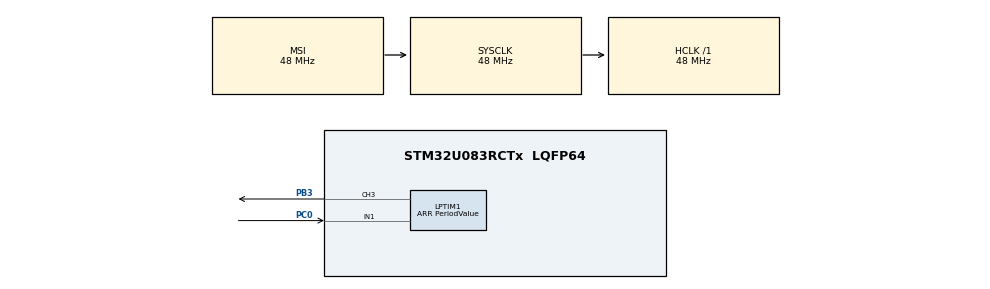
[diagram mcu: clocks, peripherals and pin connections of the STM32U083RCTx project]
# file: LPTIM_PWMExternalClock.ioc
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LPTIM1.OCPolarity_3=LPTIM_OCPOLARITY_LOW
LPTIM1.OCPulse_3=PulseValue
LPTIM1.Period=PeriodValue
Mcu.Family=STM32U0
Mcu.Name=STM32U083RCTx
Mcu.Package=LQFP64
NVIC.PriorityGroup=NVIC_PRIORITYGROUP_2
PB3.GPIO_PuPd=GPIO_PULLUP
PB3.GPIO_Speed=GPIO_SPEED_FREQ_HIGH
PB3.Signal=S_LPTIM1_CH3
PC0.Mode=Counts_external_clock_standalone_1X_occur1
PC0.Signal=LPTIM1_IN1
ProjectManager.HeapSize=0x200
ProjectManager.StackSize=0x400
ProjectManager.TargetToolchain=EWARM V9.20
RCC.ADCFreq_Value=48000000
RCC.AHBFreq_Value=48000000
RCC.CodegenConfigPeriph=false
RCC.CortexFreq_Value=48000000
RCC.HCLKFreq_Value=48000000
RCC.HSE_VALUE=4000000
RCC.HSI48_VALUE=48000000
RCC.HSI_VALUE=16000000
RCC.LSE_VALUE=32768
RCC.MSIClockRangeVal=RCC_MSIRANGE_11
RCC.MSI_VALUE=48000000
RCC.PLLM=RCC_PLLM_DIV8
RCC.PLLN=8
RCC.PLLSourceVirtual=RCC_PLLSOURCE_MSI
RCC.SYSCLKFreq_VALUE=48000000
RCC.SYSCLKSource=RCC_SYSCLKSOURCE_MSI
RCC.USBFreq_Value=48000000
RCC.VCOOutputFreq_Value=48000000
SH.S_LPTIM1_CH3.0=LPTIM1_CH3,OutputIO_CH3
VP_LPTIM1_VS_CH3.Mode=Channel_3_Active
VP_PWR_VS_SECSignals.Mode=Security/Privilege
board=custom

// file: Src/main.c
/* USER CODE BEGIN Header */
/**
  ******************************************************************************
  * @file    LPTIM/LPTIM_PWMExternalClock/Src/main.c
  * @author  MCD Application Team
  * @brief   This example describes how to configure and use LPTIM to generate a
  *          PWM at the lowest power consumption, using an external counter
  *          clock, through the STM32U0xx HAL API.
  ******************************************************************************
  * @attention
  *
  * Copyright (c) 2023 STMicroelectronics.
  * All rights reserved.
  *
  * This software is licensed under terms that can be found in the LICENSE file
  * in the root directory of this software component.
  * If no LICENSE file comes with this software, it is provided AS-IS.
  ******************************************************************************
  */
/* USER CODE END Header */
#include "main.h"

/* USER CODE BEGIN PD */
/* Set the timeout to 1000 ms */
#define TIMEOUT_VALUE 1000U

/* USER CODE END PD */

LPTIM_HandleTypeDef hlptim1;

void SystemClock_Config(void);
static void MX_GPIO_Init(void);
static void MX_LPTIM1_Init(void);

int main(void)
{
  /* USER CODE BEGIN 1 */
  uint32_t tickstart;
  /* STM32U0xx HAL library initialization:
       - Configure the Flash prefetch
       - Systick timer is configured by default as source of time base, but user
         can eventually implement his proper time base source (a general purpose
         timer for example or other time source), keeping in mind that Time base
         duration should be kept 1ms since PPP_TIMEOUT_VALUEs are defined and
         handled in milliseconds basis.
       - Low Level Initialization
     */
  /* USER CODE END 1 */

  /* MCU Configuration--------------------------------------------------------*/

  /* Reset of all peripherals, Initializes the Flash interface and the Systick. */
  HAL_Init();

  /* Configure the system clock */
  SystemClock_Config();

  /* USER CODE BEGIN SysInit */
  /* Configure LED4 */
  BSP_LED_Init(LED4);

  /* USER CODE END SysInit */

  /* Initialize all configured peripherals */
  MX_GPIO_Init();
  MX_LPTIM1_Init();
  /* USER CODE BEGIN 2 */

  /* User push-button (EXTI_Line13) will be used to wakeup the system from STOP mode */
  BSP_PB_Init(BUTTON_USER, BUTTON_MODE_EXTI);

  /* ### Start generating the PWM signal ############################## */
  /*
   *  Period = 99
   *  Pulse  = 49
   *  According to this configuration, the duty cycle will be equal to 50% and
   *  the output frequency will be equal to the input frequency divided by 100
   *  since the LPTIM have to count 100 external clock edges each period.
   */
  if (HAL_LPTIM_PWM_Start(&hlptim1, LPTIM_CHANNEL_3) != HAL_OK)
  {
    Error_Handler();
  }

  /*
   * Make sure that the counter starts before entering in stop mode. Otherwise,
   * if the external clock frequency is too low, the registers are not updated
   * on time and stop mode is entered while the counter isn't started yet.
   * Note: When starting the counter by software (TRIGEN[1:0] = 00), there is a
   *    delay of 3 kernel clock cycles between the LPTIM_CR register update (set
   *    one of SNGSTRT or CNTSTRT bits) and the effective start of the counter.
   */

  /* Init tickstart for timeout management */
  tickstart = HAL_GetTick();

  while (HAL_LPTIM_ReadCounter(&hlptim1) == 0)
  {
    if (((HAL_GetTick() - tickstart) > TIMEOUT_VALUE) || (TIMEOUT_VALUE == 0U))
    {
      /* Timeout reached */
      Error_Handler();
    }
  }

  HAL_SuspendTick();
  HAL_PWR_EnterSTOPMode(PWR_LOWPOWERREGULATOR_ON, PWR_STOPENTRY_WFI);
  /* Resume Tick interrupt if disabled prior to sleep mode entry*/
  HAL_ResumeTick();

  /* ### Stop counting when leaving Stop mode ########################## */
  if (HAL_LPTIM_PWM_Stop(&hlptim1, LPTIM_CHANNEL_3) != HAL_OK)
  {
    Error_Handler();
  }

  /* USER CODE END 2 */

  /* Infinite loop */
  while (1)
  {

  }
}

void SystemClock_Config(void)
{
  RCC_OscInitTypeDef RCC_OscInitStruct = {0};
  RCC_ClkInitTypeDef RCC_ClkInitStruct = {0};

  /** Configure the main internal regulator output voltage
  */
  HAL_PWREx_ControlVoltageScaling(PWR_REGULATOR_VOLTAGE_SCALE1);

  /** Initializes the RCC Oscillators according to the specified parameters
  * in the RCC_OscInitTypeDef structure.
  */
  RCC_OscInitStruct.OscillatorType = RCC_OSCILLATORTYPE_MSI;
  RCC_OscInitStruct.MSIState = RCC_MSI_ON;
  RCC_OscInitStruct.MSICalibrationValue = RCC_MSICALIBRATION_DEFAULT;
  RCC_OscInitStruct.MSIClockRange = RCC_MSIRANGE_11;
  if (HAL_RCC_OscConfig(&RCC_OscInitStruct) != HAL_OK)
  {
    Error_Handler();
  }

  /** Initializes the CPU, AHB and APB buses clocks
  */
  RCC_ClkInitStruct.ClockType = RCC_CLOCKTYPE_HCLK|RCC_CLOCKTYPE_SYSCLK
                              |RCC_CLOCKTYPE_PCLK1;
  RCC_ClkInitStruct.SYSCLKSource = RCC_SYSCLKSOURCE_MSI;
  RCC_ClkInitStruct.AHBCLKDivider = RCC_SYSCLK_DIV1;
  RCC_ClkInitStruct.APB1CLKDivider = RCC_HCLK_DIV1;

  if (HAL_RCC_ClockConfig(&RCC_ClkInitStruct, FLASH_LATENCY_1) != HAL_OK)
  {
    Error_Handler();
  }
}

static void MX_LPTIM1_Init(void)
{

  LPTIM_OC_ConfigTypeDef sConfig1 = {0};

  hlptim1.Instance = LPTIM1;
  hlptim1.Init.Clock.Source = LPTIM_CLOCKSOURCE_ULPTIM;
  hlptim1.Init.Clock.Prescaler = LPTIM_PRESCALER_DIV1;
  hlptim1.Init.UltraLowPowerClock.Polarity = LPTIM_CLOCKPOLARITY_RISING;
  hlptim1.Init.UltraLowPowerClock.SampleTime = LPTIM_CLOCKSAMPLETIME_DIRECTTRANSITION;
  hlptim1.Init.Trigger.Source = LPTIM_TRIGSOURCE_SOFTWARE;
  hlptim1.Init.Period = PeriodValue;
  hlptim1.Init.UpdateMode = LPTIM_UPDATE_IMMEDIATE;
  hlptim1.Init.CounterSource = LPTIM_COUNTERSOURCE_EXTERNAL;
  hlptim1.Init.Input1Source = LPTIM_INPUT1SOURCE_GPIO;
  hlptim1.Init.Input2Source = LPTIM_INPUT2SOURCE_GPIO;
  hlptim1.Init.RepetitionCounter = 0;
  if (HAL_LPTIM_Init(&hlptim1) != HAL_OK)
  {
    Error_Handler();
  }

  sConfig1.Pulse = PulseValue;
  sConfig1.OCPolarity = LPTIM_OCPOLARITY_LOW;
  if (HAL_LPTIM_OC_ConfigChannel(&hlptim1, &sConfig1, LPTIM_CHANNEL_3) != HAL_OK)
  {
    Error_Handler();
  }
  HAL_LPTIM_MspPostInit(&hlptim1);

}

static void MX_GPIO_Init(void)
{

  /* GPIO Ports Clock Enable */
  __HAL_RCC_GPIOC_CLK_ENABLE();
  __HAL_RCC_GPIOB_CLK_ENABLE();

}

void Error_Handler(void)
{
  /* USER CODE BEGIN Error_Handler_Debug */
  /* Turn LED4 on */
  BSP_LED_On(LED4);
  while(1)
  {
  }
  /* USER CODE END Error_Handler_Debug */
}
